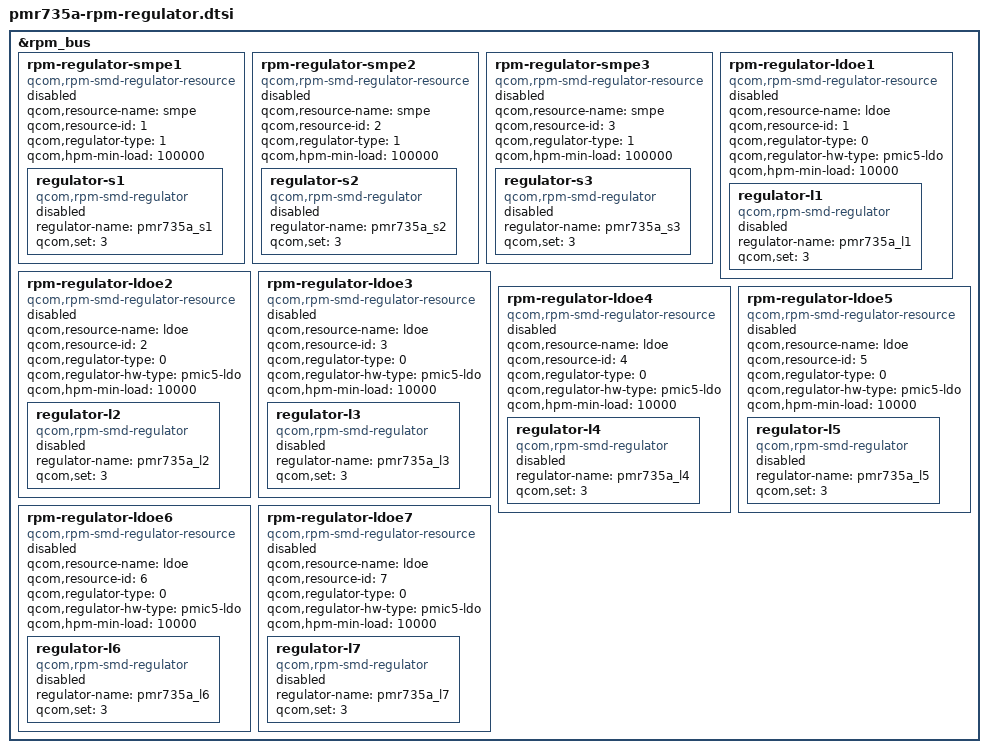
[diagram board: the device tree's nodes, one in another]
&rpm_bus {
	rpm-regulator-smpe1 {
		compatible = "qcom,rpm-smd-regulator-resource";
		qcom,resource-name = "smpe";
		qcom,resource-id = <1>;
		qcom,regulator-type = <1>;
		qcom,hpm-min-load = <100000>;
		status = "disabled";

		regulator-s1 {
			compatible = "qcom,rpm-smd-regulator";
			regulator-name = "pmr735a_s1";
			qcom,set = <3>;
			status = "disabled";
		};
	};

	rpm-regulator-smpe2 {
		compatible = "qcom,rpm-smd-regulator-resource";
		qcom,resource-name = "smpe";
		qcom,resource-id = <2>;
		qcom,regulator-type = <1>;
		qcom,hpm-min-load = <100000>;
		status = "disabled";

		regulator-s2 {
			compatible = "qcom,rpm-smd-regulator";
			regulator-name = "pmr735a_s2";
			qcom,set = <3>;
			status = "disabled";
		};
	};

	rpm-regulator-smpe3 {
		compatible = "qcom,rpm-smd-regulator-resource";
		qcom,resource-name = "smpe";
		qcom,resource-id = <3>;
		qcom,regulator-type = <1>;
		qcom,hpm-min-load = <100000>;
		status = "disabled";

		regulator-s3 {
			compatible = "qcom,rpm-smd-regulator";
			regulator-name = "pmr735a_s3";
			qcom,set = <3>;
			status = "disabled";
		};
	};

	rpm-regulator-ldoe1 {
		compatible = "qcom,rpm-smd-regulator-resource";
		qcom,resource-name = "ldoe";
		qcom,resource-id = <1>;
		qcom,regulator-type = <0>;
		qcom,regulator-hw-type = "pmic5-ldo";
		qcom,hpm-min-load = <10000>;
		status = "disabled";

		regulator-l1 {
			compatible = "qcom,rpm-smd-regulator";
			regulator-name = "pmr735a_l1";
			qcom,set = <3>;
			status = "disabled";
		};
	};

	rpm-regulator-ldoe2 {
		compatible = "qcom,rpm-smd-regulator-resource";
		qcom,resource-name = "ldoe";
		qcom,resource-id = <2>;
		qcom,regulator-type = <0>;
		qcom,regulator-hw-type = "pmic5-ldo";
		qcom,hpm-min-load = <10000>;
		status = "disabled";

		regulator-l2 {
			compatible = "qcom,rpm-smd-regulator";
			regulator-name = "pmr735a_l2";
			qcom,set = <3>;
			status = "disabled";
		};
	};

	rpm-regulator-ldoe3 {
		compatible = "qcom,rpm-smd-regulator-resource";
		qcom,resource-name = "ldoe";
		qcom,resource-id = <3>;
		qcom,regulator-type = <0>;
		qcom,regulator-hw-type = "pmic5-ldo";
		qcom,hpm-min-load = <10000>;
		status = "disabled";

		regulator-l3 {
			compatible = "qcom,rpm-smd-regulator";
			regulator-name = "pmr735a_l3";
			qcom,set = <3>;
			status = "disabled";
		};
	};

	rpm-regulator-ldoe4 {
		compatible = "qcom,rpm-smd-regulator-resource";
		qcom,resource-name = "ldoe";
		qcom,resource-id = <4>;
		qcom,regulator-type = <0>;
		qcom,regulator-hw-type = "pmic5-ldo";
		qcom,hpm-min-load = <10000>;
		status = "disabled";

		regulator-l4 {
			compatible = "qcom,rpm-smd-regulator";
			regulator-name = "pmr735a_l4";
			qcom,set = <3>;
			status = "disabled";
		};
	};

	rpm-regulator-ldoe5 {
		compatible = "qcom,rpm-smd-regulator-resource";
		qcom,resource-name = "ldoe";
		qcom,resource-id = <5>;
		qcom,regulator-type = <0>;
		qcom,regulator-hw-type = "pmic5-ldo";
		qcom,hpm-min-load = <10000>;
		status = "disabled";

		regulator-l5 {
			compatible = "qcom,rpm-smd-regulator";
			regulator-name = "pmr735a_l5";
			qcom,set = <3>;
			status = "disabled";
		};
	};

	rpm-regulator-ldoe6 {
		compatible = "qcom,rpm-smd-regulator-resource";
		qcom,resource-name = "ldoe";
		qcom,resource-id = <6>;
		qcom,regulator-type = <0>;
		qcom,regulator-hw-type = "pmic5-ldo";
		qcom,hpm-min-load = <10000>;
		status = "disabled";

		regulator-l6 {
			compatible = "qcom,rpm-smd-regulator";
			regulator-name = "pmr735a_l6";
			qcom,set = <3>;
			status = "disabled";
		};
	};

	rpm-regulator-ldoe7 {
		compatible = "qcom,rpm-smd-regulator-resource";
		qcom,resource-name = "ldoe";
		qcom,resource-id = <7>;
		qcom,regulator-type = <0>;
		qcom,regulator-hw-type = "pmic5-ldo";
		qcom,hpm-min-load = <10000>;
		status = "disabled";

		regulator-l7 {
			compatible = "qcom,rpm-smd-regulator";
			regulator-name = "pmr735a_l7";
			qcom,set = <3>;
			status = "disabled";
		};
	};
};
